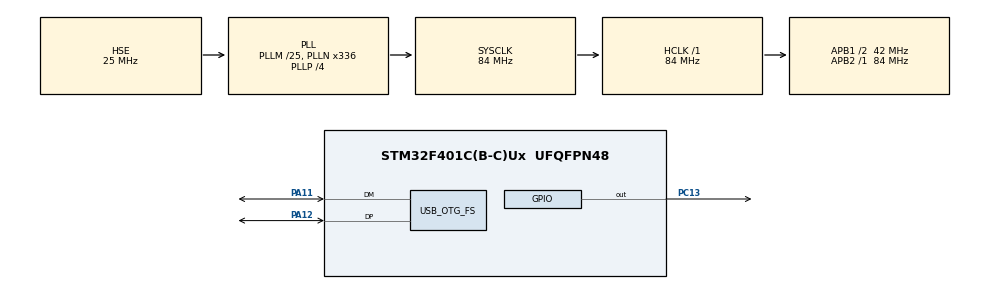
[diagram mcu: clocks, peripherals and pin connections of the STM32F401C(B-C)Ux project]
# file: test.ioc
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Mcu.Family=STM32F4
Mcu.Name=STM32F401C(B-C)Ux
Mcu.Package=UFQFPN48
NVIC.OTG_FS_IRQn=true\:0\:0\:false\:false\:true\:false\:true\:true
NVIC.PriorityGroup=NVIC_PRIORITYGROUP_4
PA11.Mode=Device_Only
PA11.Signal=USB_OTG_FS_DM
PA12.Mode=Device_Only
PA12.Signal=USB_OTG_FS_DP
PA13.Mode=Serial_Wire
PA13.Signal=SYS_JTMS-SWDIO
PA14.Mode=Serial_Wire
PA14.Signal=SYS_JTCK-SWCLK
PC13-ANTI_TAMP.Signal=GPIO_Output
PH0\ -\ OSC_IN.Mode=HSE-External-Oscillator
PH0\ -\ OSC_IN.Signal=RCC_OSC_IN
PH1\ -\ OSC_OUT.Mode=HSE-External-Oscillator
PH1\ -\ OSC_OUT.Signal=RCC_OSC_OUT
ProjectManager.HeapSize=0x200
ProjectManager.StackSize=0x400
ProjectManager.TargetToolchain=MDK-ARM V5.32
RCC.48MHZClocksFreq_Value=48000000
RCC.AHBFreq_Value=84000000
RCC.APB1CLKDivider=RCC_HCLK_DIV2
RCC.APB1Freq_Value=42000000
RCC.APB1TimFreq_Value=84000000
RCC.APB2Freq_Value=84000000
RCC.APB2TimFreq_Value=84000000
RCC.CortexFreq_Value=84000000
RCC.HCLKFreq_Value=84000000
RCC.HSE_VALUE=25000000
RCC.HSI_VALUE=16000000
RCC.LSE_VALUE=32768
RCC.PLLM=25
RCC.PLLN=336
RCC.PLLP=RCC_PLLP_DIV4
RCC.PLLQ=7
RCC.SYSCLKFreq_VALUE=84000000
RCC.SYSCLKSource=RCC_SYSCLKSOURCE_PLLCLK
RCC.VCOOutputFreq_Value=336000000
USB_DEVICE.CLASS_NAME_FS=HID
USB_DEVICE.VirtualMode=Hid
USB_DEVICE.VirtualModeFS=Hid_FS
USB_OTG_FS.VirtualMode=Device_Only
VP_USB_DEVICE_VS_USB_DEVICE_HID_FS.Mode=HID_FS
board=custom

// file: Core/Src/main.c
/* USER CODE BEGIN Header */
/**
  ******************************************************************************
  * @file           : main.c
  * @brief          : Main program body
  ******************************************************************************
  * @attention
  *
  * Copyright (c) 2023 STMicroelectronics.
  * All rights reserved.
  *
  * This software is licensed under terms that can be found in the LICENSE file
  * in the root directory of this software component.
  * If no LICENSE file comes with this software, it is provided AS-IS.
  *
  ******************************************************************************
  */
/* USER CODE END Header */
#include "main.h"
#include "usb_device.h"
#include "gpio.h"
#include "adc.h"
/* USER CODE BEGIN Includes */
#include "usbd_hid.h"
#include "stdbool.h"
#include "encoder.h"
/* USER CODE END Includes */

/* USER CODE BEGIN PV */

extern USBD_HandleTypeDef hUsbDeviceFS;
uint8_t midiNoteOn[4];
uint8_t midiNoteOff[4];
float _err_estimate;
uint16_t newEncoderValue = 0;
uint16_t oldEncoderValue_1 = 0;
uint16_t oldEncoderValue_3 = 0;
uint16_t oldEncoderValue_4 = 0;
NoteOnOff butON = {0x09, 0x90, 0, 0x7F};
NoteOnOff Sensing = {MIDI_ACTIVE_SENSING, 0, 0, 0};
uint16_t x = 0;

/* USER CODE END PV */

void SystemClock_Config(void);
/* USER CODE BEGIN PFP */
void encoder(uint16_t newEncoderValue, uint16_t* oldEncoderValue, uint8_t num, uint32_t CR);
/* USER CODE END PFP */

/* USER CODE BEGIN 0 */
enum {UP = 0,DOWN = 0x10}direction;
/* USER CODE END 0 */

int main(void)
{

  /* MCU Configuration--------------------------------------------------------*/

  /* Reset of all peripherals, Initializes the Flash interface and the Systick. */
  HAL_Init();

  /* Configure the system clock */
  SystemClock_Config();

  /* Initialize all configured peripherals */
  MX_GPIO_Init();
  MX_USB_DEVICE_Init();
	Encoder_init();
  /* Infinite loop */
  /* USER CODE BEGIN WHILE */
  while (1)
  {
		encoder(TIM1->CNT,&oldEncoderValue_1,1,TIM1->CR1);
		encoder(TIM3->CNT,&oldEncoderValue_3,3,TIM3->CR1);
		encoder(TIM4->CNT,&oldEncoderValue_4,4,TIM4->CR1);
		++x;
		if(x>65534)USBD_HID_SendReport(&hUsbDeviceFS, (uint8_t*)&Sensing, 4);

    /* USER CODE END WHILE */

  }
}

void SystemClock_Config(void)
{
  RCC_OscInitTypeDef RCC_OscInitStruct = {0};
  RCC_ClkInitTypeDef RCC_ClkInitStruct = {0};

  /** Configure the main internal regulator output voltage
  */
  __HAL_RCC_PWR_CLK_ENABLE();
  __HAL_PWR_VOLTAGESCALING_CONFIG(PWR_REGULATOR_VOLTAGE_SCALE2);

  /** Initializes the RCC Oscillators according to the specified parameters
  * in the RCC_OscInitTypeDef structure.
  */
  RCC_OscInitStruct.OscillatorType = RCC_OSCILLATORTYPE_HSE;
  RCC_OscInitStruct.HSEState = RCC_HSE_ON;
  RCC_OscInitStruct.PLL.PLLState = RCC_PLL_ON;
  RCC_OscInitStruct.PLL.PLLSource = RCC_PLLSOURCE_HSE;
  RCC_OscInitStruct.PLL.PLLM = 25;
  RCC_OscInitStruct.PLL.PLLN = 336;
  RCC_OscInitStruct.PLL.PLLP = RCC_PLLP_DIV4;
  RCC_OscInitStruct.PLL.PLLQ = 7;
  if (HAL_RCC_OscConfig(&RCC_OscInitStruct) != HAL_OK)
  {
    Error_Handler();
  }

  /** Initializes the CPU, AHB and APB buses clocks
  */
  RCC_ClkInitStruct.ClockType = RCC_CLOCKTYPE_HCLK|RCC_CLOCKTYPE_SYSCLK
                              |RCC_CLOCKTYPE_PCLK1|RCC_CLOCKTYPE_PCLK2;
  RCC_ClkInitStruct.SYSCLKSource = RCC_SYSCLKSOURCE_PLLCLK;
  RCC_ClkInitStruct.AHBCLKDivider = RCC_SYSCLK_DIV1;
  RCC_ClkInitStruct.APB1CLKDivider = RCC_HCLK_DIV2;
  RCC_ClkInitStruct.APB2CLKDivider = RCC_HCLK_DIV1;

  if (HAL_RCC_ClockConfig(&RCC_ClkInitStruct, FLASH_LATENCY_2) != HAL_OK)
  {
    Error_Handler();
  }
}

/* USER CODE BEGIN 4 */
void send_cc_message(uint8_t channel, uint8_t controller, uint8_t value) {
    uint8_t midi_data[4] = {0x0B, 0x00, 0x00, 0x00};  // MIDI CC сообщение
    midi_data[1] = 0xB0 | (channel & 0x0F);  // статусный байт
    midi_data[2] = controller & 0x7F;  // номер контроллера
    midi_data[3] = value & 0x7F;  // значение фейдера
		USBD_HID_SendReport(&hUsbDeviceFS, (uint8_t*)&midi_data, 4);// отправка MIDI сообщения
}
void send_note_message(uint8_t note){
	butON.MIDINote = note;
	USBD_HID_SendReport(&hUsbDeviceFS, (uint8_t*)&butON, 4);
}
void encoder(uint16_t newEncoderValue, uint16_t* oldEncoderValue, uint8_t num, uint32_t CR){
		if(newEncoderValue != *oldEncoderValue){
			direction =  CR & 0x10;
			if(!direction) send_cc_message(0,num,1);
			else send_cc_message(0,num,2);
			HAL_Delay(100);
			*oldEncoderValue = newEncoderValue;}
}
void delay_ms(uint16_t ms){
   RCC->APB2ENR |= RCC_APB2ENR_TIM11EN;                                         // Включаем тактирование таймера
	 ms=ms*10;
	 TIM11->PSC = 8400-1;                                                         // устанавливаем предделитель 84,000,000 / 8399 = 10,000  0,0001s
   TIM11->ARR = ms - 1;                                                         // устанавливаем значение переполнения таймера
	 TIM11->EGR |= TIM_EGR_UG;                                                    // Генерируем Событие обновления для записи данных в регистры PSC и ARR
   TIM11->CR1 |= TIM_CR1_CEN|TIM_CR1_OPM;                                       // Запускаем таймер записью бита CEN и устанавливаем режим Одного прохода установкой бита OPM
	 while (TIM11->CR1 & TIM_CR1_CEN);                                            // Ждем окончания счета
}// END_delay_ms

/* USER CODE END 4 */

void Error_Handler(void)
{
  __disable_irq();
  while (1)
  {
  }
}
